# HC32M413 register map
File version: 1.0
CPU: CM4 r0p1, little endian, MPU, FPU, 4 interrupt priority bits
Registers are 32-bit, read-write, reset 0x0 unless marked. A register's access mark holds for its fields unless they carry their own. Offsets are from the block's base; [hi:lo] are bit positions; {n}, {i} and the like mark numbered series.

## ADC
Base 0x40030000
0x00 STR 8-bit
  [0] STRT
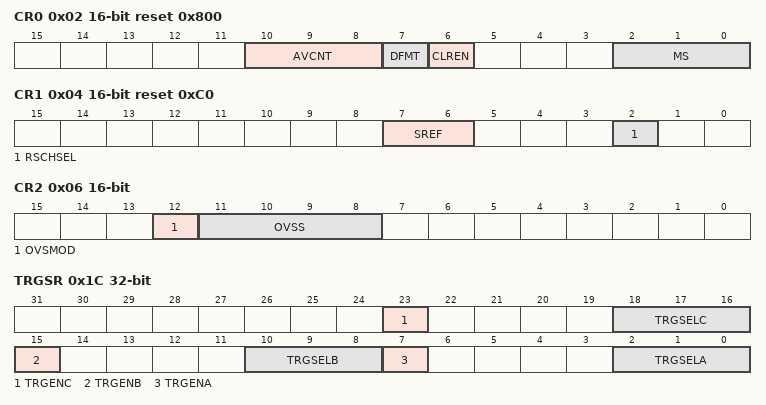
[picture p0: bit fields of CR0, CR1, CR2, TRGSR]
0x02 CR0 16-bit reset 0x800
  [10:8] AVCNT, [7] DFMT, [6] CLREN, [2:0] MS
0x04 CR1 16-bit reset 0xC0
  [7:6] SREF, [2] RSCHSEL
0x06 CR2 16-bit
  [12] OVSMOD, [11:8] OVSS
0x0C CHSELRA
  [15:0] CHSELA
0x10 CHSELRB
  [15:0] CHSELB
0x14 AVCHSELR
  [15:0] AVCHSEL
0x1C TRGSR
  [23] TRGENC, [18:16] TRGSELC, [15] TRGENB, [10:8] TRGSELB, [7] TRGENA, [2:0] TRGSELA
{0x20+i} SSTR{i} 8-bit reset 0x4 (i=0..15)
0x40 CHSELRC
  [15:0] CHSELC
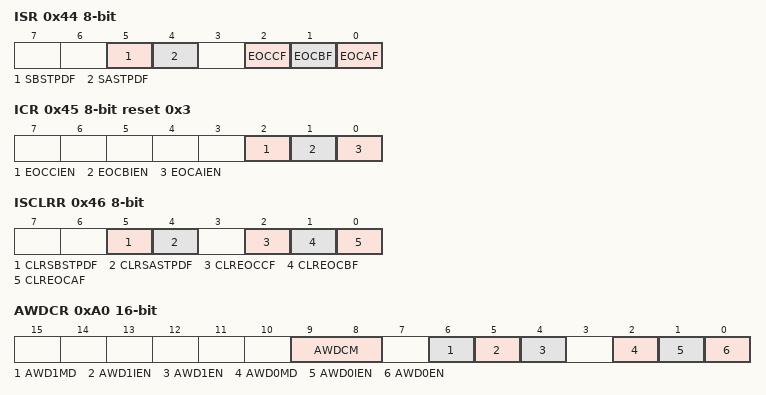
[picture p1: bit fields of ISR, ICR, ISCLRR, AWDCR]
0x44 ISR 8-bit ro
  [5] SBSTPDF, [4] SASTPDF, [2] EOCCF, [1] EOCBF, [0] EOCAF
0x45 ICR 8-bit reset 0x3
  [2] EOCCIEN, [1] EOCBIEN, [0] EOCAIEN
0x46 ISCLRR 8-bit wo
  [5] CLRSBSTPDF, [4] CLRSASTPDF, [2] CLREOCCF, [1] CLREOCBF, [0] CLREOCAF
{0x50+2i} DR{i} 16-bit ro (i=0..15)
0xA0 AWDCR 16-bit
  [9:8] AWDCM, [6] AWD1MD, [5] AWD1IEN, [4] AWD1EN, [2] AWD0MD, [1] AWD0IEN, [0] AWD0EN
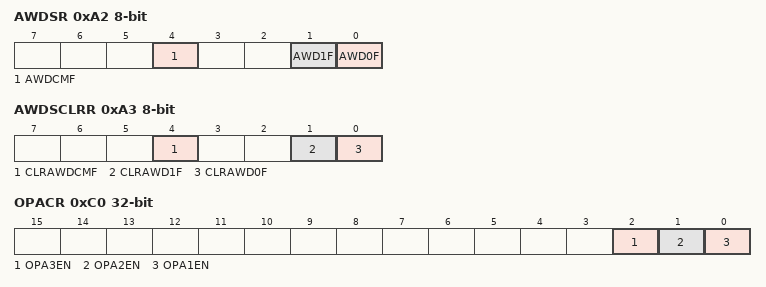
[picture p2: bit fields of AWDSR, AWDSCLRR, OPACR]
0xA2 AWDSR 8-bit ro
  [4] AWDCMF, [1] AWD1F, [0] AWD0F
0xA3 AWDSCLRR 8-bit
  [4] CLRAWDCMF, [1] CLRAWD1F, [0] CLRAWD0F
0xA4 AWD0DR0 16-bit
0xA6 AWD0DR1 16-bit reset 0xFFFF
0xA8 AWD0CHSR 8-bit
  [4:0] AWDCH
0xAC AWD1DR0 16-bit
0xAE AWD1DR1 16-bit reset 0xFFFF
0xB0 AWD1CHSR 8-bit
  [4:0] AWDCH
0xC0 OPACR
  [2] OPA3EN, [1] OPA2EN, [0] OPA1EN

## AOS
Base 0x40010800
0x00 INTSFTTRG wo
  [0] STRG
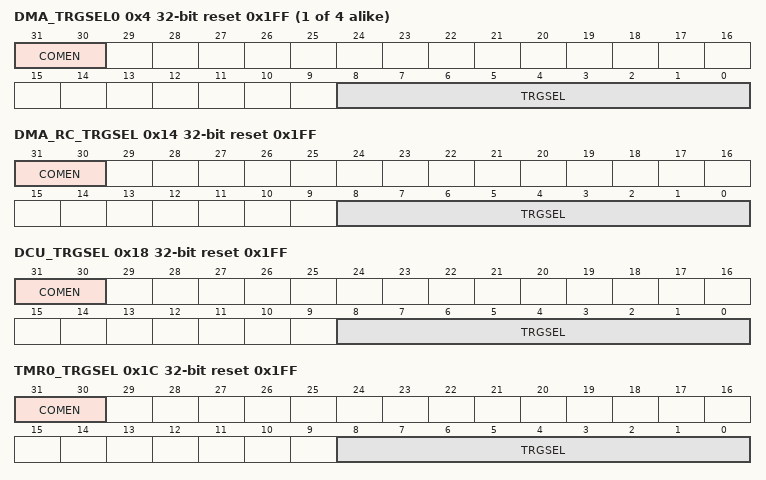
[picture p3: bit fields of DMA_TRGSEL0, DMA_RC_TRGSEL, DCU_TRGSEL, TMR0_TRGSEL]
{0x4+4i} DMA_TRGSEL{i} reset 0x1FF (i=0..3)
  [31:30] COMEN, [8:0] TRGSEL
0x14 DMA_RC_TRGSEL reset 0x1FF
  [31:30] COMEN, [8:0] TRGSEL
0x18 DCU_TRGSEL reset 0x1FF
  [31:30] COMEN, [8:0] TRGSEL
0x1C TMR0_TRGSEL reset 0x1FF
  [31:30] COMEN, [8:0] TRGSEL
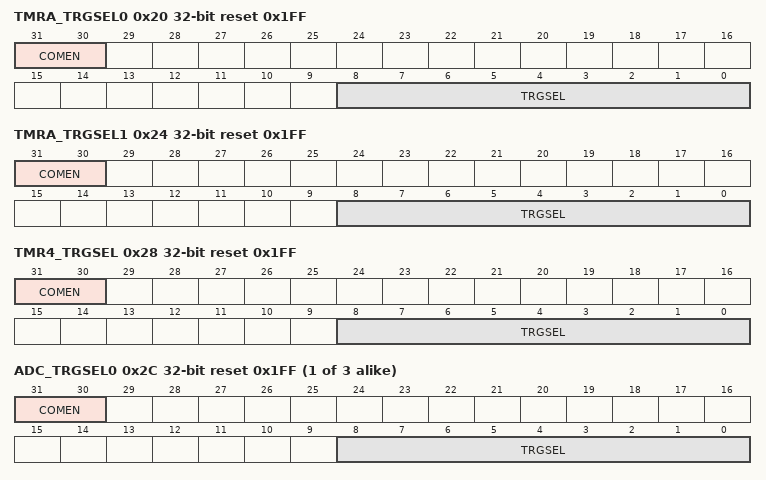
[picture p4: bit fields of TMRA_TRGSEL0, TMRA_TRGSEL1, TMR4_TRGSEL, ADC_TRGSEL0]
0x20 TMRA_TRGSEL0 reset 0x1FF
  [31:30] COMEN, [8:0] TRGSEL
0x24 TMRA_TRGSEL1 reset 0x1FF
  [31:30] COMEN, [8:0] TRGSEL
0x28 TMR4_TRGSEL reset 0x1FF
  [31:30] COMEN, [8:0] TRGSEL
{0x2C+4i} ADC_TRGSEL{i} reset 0x1FF (i=0..2)
  [31:30] COMEN, [8:0] TRGSEL
0x38 COMTRGSEL1 reset 0x1FF
  [8:0] COMTRG
0x3C COMTRGSEL2 reset 0x1FF
  [8:0] COMTRG

## CMP1 — desc CMP
Base 0x4004A000
Same registers: CMP2 0x4004A100, CMP3 0x4004A400
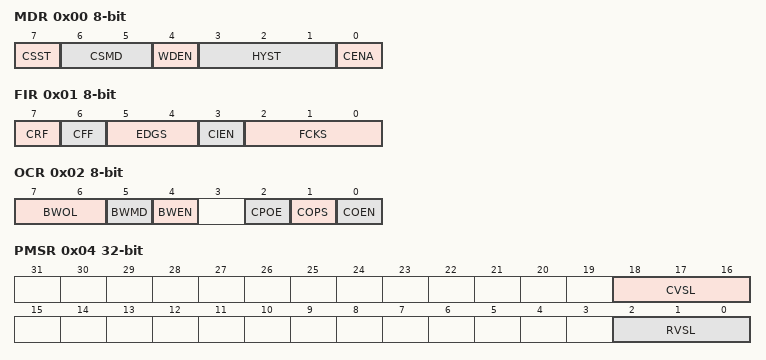
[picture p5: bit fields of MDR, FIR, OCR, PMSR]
0x00 MDR 8-bit
  [7] CSST, [6:5] CSMD, [4] WDEN, [3:1] HYST, [0] CENA
0x01 FIR 8-bit
  [7] CRF, [6] CFF, [5:4] EDGS, [3] CIEN, [2:0] FCKS
0x02 OCR 8-bit
  [7:6] BWOL, [5] BWMD, [4] BWEN, [2] CPOE, [1] COPS, [0] COEN
0x03 OMR 8-bit ro
  [0] CMON
0x04 PMSR
  [18:16] CVSL, [2:0] RVSL
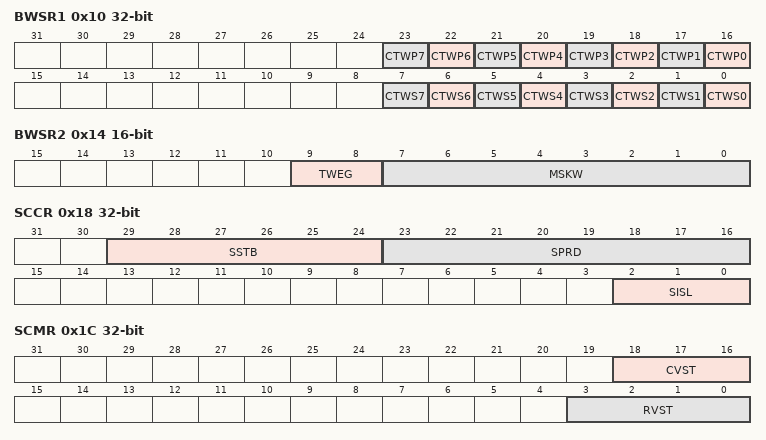
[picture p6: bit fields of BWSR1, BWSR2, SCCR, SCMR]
0x10 BWSR1
  [n+16] CTWP{n} (n=0..7), [n] CTWS{n} (n=0..7)
0x14 BWSR2 16-bit
  [9:8] TWEG, [7:0] MSKW
0x18 SCCR
  [29:24] SSTB, [23:16] SPRD, [2:0] SISL
0x1C SCMR
  [18:16] CVST, [3:0] RVST

## CMP_COMMON
Base 0x4004A000; alternate view of CMP1
0x0C DADR 16-bit
  [11:0] DADR
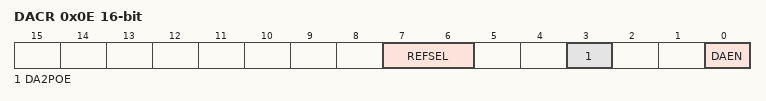
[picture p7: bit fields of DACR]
0x0E DACR 16-bit
  [7:6] REFSEL, [3] DA2POE, [0] DAEN

## CMU
Base 0x40054400
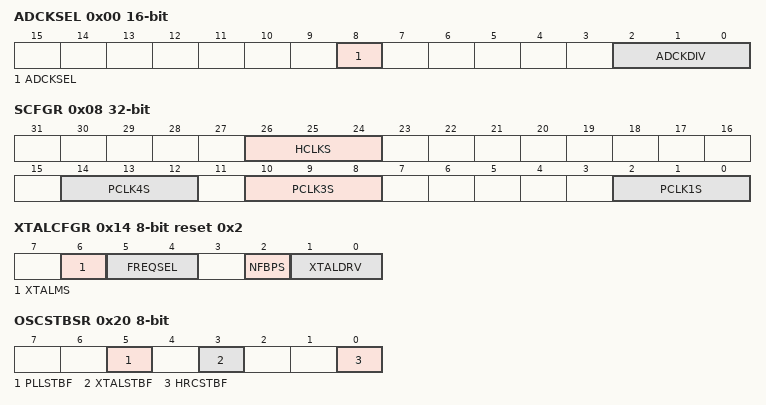
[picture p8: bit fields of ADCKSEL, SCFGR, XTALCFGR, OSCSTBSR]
0x00 ADCKSEL 16-bit
  [8] ADCKSEL, [2:0] ADCKDIV
0x04 XTALSTDSR 8-bit
  [0] XTALSTDF
0x08 SCFGR
  [26:24] HCLKS, [14:12] PCLK4S, [10:8] PCLK3S, [2:0] PCLK1S
0x0C CKSWR 8-bit reset 0x1
  [2:0] CKSW
0x10 XTALCR 8-bit reset 0x1
  [0] XTALSTP
0x14 XTALCFGR 8-bit reset 0x2
  [6] XTALMS, [5:4] FREQSEL, [2] NFBPS, [1:0] XTALDRV
0x15 XTALSTBCR 8-bit
  [2:0] XTALSTB
0x18 HRCCR 8-bit
  [0] HRCSTP
0x20 OSCSTBSR 8-bit ro
  [5] PLLSTBF, [3] XTALSTBF, [0] HRCSTBF
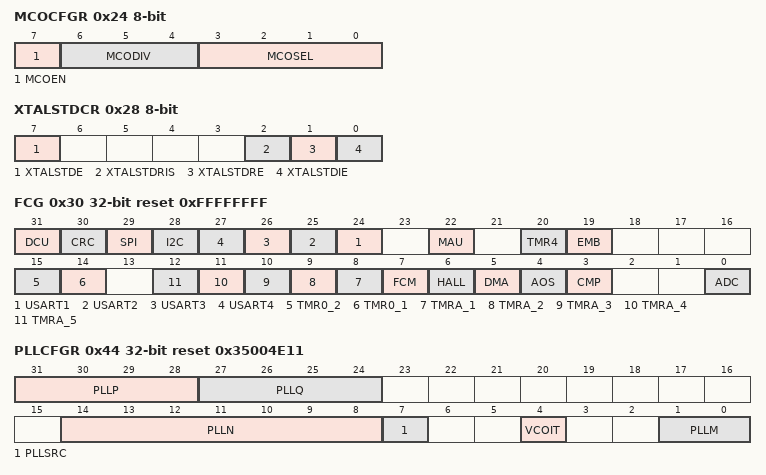
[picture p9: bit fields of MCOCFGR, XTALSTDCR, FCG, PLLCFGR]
0x24 MCOCFGR 8-bit
  [7] MCOEN, [6:4] MCODIV, [3:0] MCOSEL
0x28 XTALSTDCR 8-bit
  [7] XTALSTDE, [2] XTALSTDRIS, [1] XTALSTDRE, [0] XTALSTDIE
0x30 FCG reset 0xFFFFFFFF
  [31] DCU, [30] CRC, [29] SPI, [28] I2C, [n+23] USART{n} (n=1..4), [22] MAU, [20] TMR4, [19] EMB, [15] TMR0_2, [14] TMR0_1, [n+7] TMRA_{n} (n=1..5), [7] FCM, [6] HALL, [5] DMA, [4] AOS, [3] CMP, [0] ADC
0x3C LRCCR 8-bit
  [0] LRCSTP
0x40 MRCCR 8-bit
  [0] MRCSTP
0x44 PLLCFGR reset 0x35004E11
  [31:28] PLLP, [27:24] PLLQ, [14:8] PLLN, [7] PLLSRC, [4] VCOIT, [1:0] PLLM
0x48 PLLCR 8-bit reset 0x1
  [0] PLLOFF
